# nrf54h20_enga_application register map
Vendor: Nordic Semiconductor; Series: nRF54h; File version: 1
CPU: CM33 r0p4, little endian, MPU, FPU, 3 interrupt priority bits, 480 interrupts, 4 SAU regions
Registers are 32-bit, read-write, reset 0x0 unless marked. A register's access mark holds for its fields unless they carry their own. Offsets are from the block's base; [hi:lo] are bit positions; {n}, {i} and the like mark numbered series; 'fields as' and 'values as' point back to an identical list; <NAME> marks a mode.

## GLOBAL_STM_NS — System Trace Macrocell
Base 0xBF042000
0xC10 DMACTLR — Controls the DMA transfer request mechanism.
  [3:2] SENS — Determines the sensitivity of the DMA request to the current buffer level in the STM
    0=LT25 (Buffer is <25 percent full.); 1=LT50 (Buffer is <50 percent full.); 2=LT75 (Buffer is <75 percent full.); 3=LT100 (Buffer is <100 percent full.)
0xDF4 HEMASTR ro — Indicates the STPv2 master number of hardware event trace. This number is the master number presented in STPv2.
  [16:0] MASTER — The STPv2 master number that hardware event traces should be associated with.
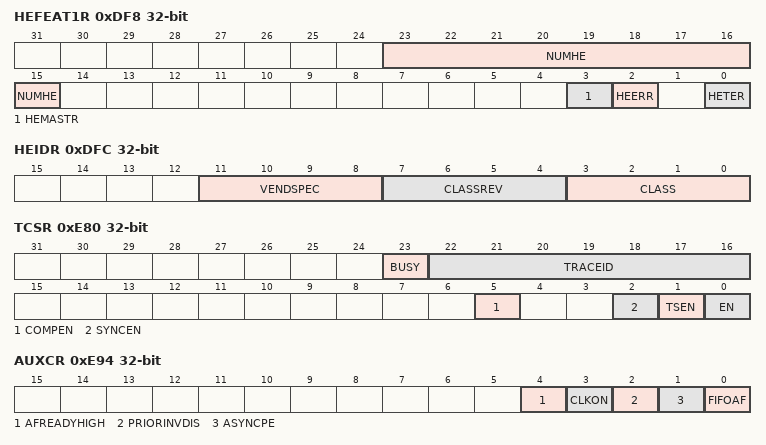
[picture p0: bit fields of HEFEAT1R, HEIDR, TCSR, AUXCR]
0xDF8 HEFEAT1R ro — Indicates the features of the STM.
  [23:15] NUMHE — The number of hardware events supported by the STM
  [3] HEMASTR — STMHEMASTR support
    0=NotImplemented (The feature is not implemented.); 1=Implemented (The feature is implemented.)
  [2] HEERR — Hardware event error detection support
    values as HEMASTR
  [0] HETER — STMHETER support
    values as HEMASTR
0xDFC HEIDR ro — Indicates the features of hardware event tracing in the STM.
  [11:8] VENDSPEC — The VENDSPEC field identifies any vendor specific modifications or mappings
  [7:4] CLASSREV — The CLASSREV field identifies the revision of the programmers model
  [3:0] CLASS — The CLASS field identifies the programmers model
    1=Hardware Event Control programmers model
0xE80 TCSR — Controls the STM settings.
  [23] BUSY — STM is busy, for example the STM trace FIFO is not empty.
    0=Ready (STM is not busy.); 1=Busy (STM is busy.)
  [22:16] TRACEID — ATB Trace ID. Setting this value to all zeroes might result in Unpredictable tracing.
  [5] COMPEN — Compression Enable for Stimulus Ports.
    0=Disabled (Compression disabled, data transfers are transmitted at the size of the transaction.); 1=Enabled (Compression enabled, data transfers are compressed to save bandwidth.)
  [2] SYNCEN — STMSYNCR is implemented so this value is Read As One.
    0=Disabled (The STM Sync feature is disabled.); 1=Enabled (The STM Sync feature is enabled.)
  [1] TSEN — Enable or disable timestamp bundling.
    0=Disabled (Time stamps are disabled. Requests for timestamp generation are ignored, and stimulus port writes selecting timestamping are treated as if it were not selected.); 1=Enabled (Time stamps are enabled. If stimulus writes select timestamping, a timestamp is output according to STPv2.)
  [0] EN — Global STM enable
    0=Disabled (The STM is disabled.); 1=Enabled (The STM is enabled.)
0xE94 AUXCR — Used for implementation defined STM controls.
  [4] AFREADYHIGH — Provides override control for the AFREADY output
    0=Disabled (No override, AFREADY is controlled by the state of STM.); 1=Enabled (Override, AFREADY is driven HIGH.)
  [3] CLKON — Provides override control for architectural clock gate enable.
    0=Disabled (No override, clock gate is controlled by the state of STM.); 1=Enabled (Override, clock is enabled.)
  [2] PRIORINVDIS — Controls arbitration between AXI and HW during flush.
    0=Enabled (Priority inversion, when AXI flush is finished, HW gets priority until HW flush is done.); 1=Disabled (Priority inversion disabled, AXI always has priority over HW.)
  [1] ASYNCPE — Is ASYNC priority higher than trace?
    0=Lower (ASYNC priority is always lower than trace.); 1=Escalate (ASYNC priority escalates on second synchronization request.)
  [0] FIFOAF — FIFO Auto-flush.
    0=Disabled (Auto-flush is disabled.); 1=Enabled (Auto-flush is enabled. The STM automatically drains all data it has even if the ATB interface is not fully utilized.)
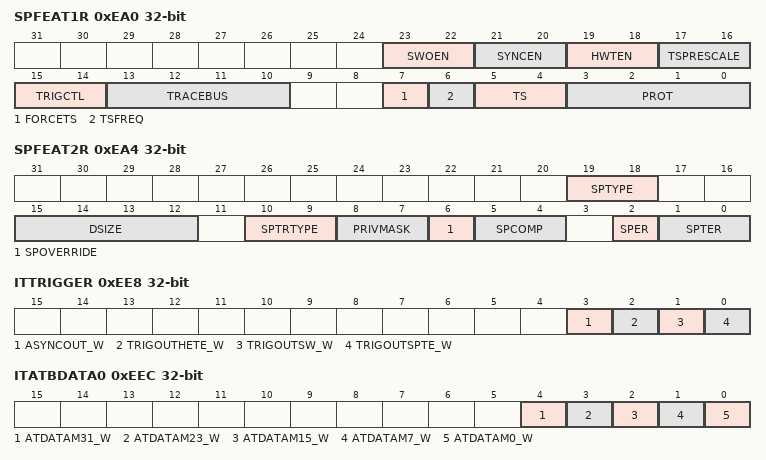
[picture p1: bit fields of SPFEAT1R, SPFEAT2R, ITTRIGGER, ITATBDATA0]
0xEA0 SPFEAT1R — Indicates the features of the STM.
  [23:22] SWOEN — STMTCSR.SWOEN support
    1=NotImplemented (STMTCSR.SWOEN not implemented)
  [21:20] SYNCEN — STMTCSR.SYNCEN support
    2=ReadAsOne (STMTCSR.SYNCEN implemented but always reads as b1)
  [19:18] HWTEN — STMTCSR.HWTEN support
    1=NotImplemented (STMTCSR.HWTEN is not implemented)
  [17:16] TSPRESCALE — Timestamp prescale support
    0=NotImplemented (Timestamp prescale is not implemented.); 1=Implemented (Timestamp prescale is implemented.)
  [15:14] TRIGCTL — Trigger control support.
  [13:10] TRACEBUS — Trace bus support.
  [7] FORCETS — Timestamp force configuration.
    0=NotImplemented (STMTSSTIMR bit 0 is read-only.); 1=Implemented (STMTSSTIMR bit 0 is read-write.)
  [6] TSFREQ — Timestamp frequency indication configuration.
    0=NotImplemented (STMTSFREQR is read-only.); 1=Implemented (STMTSFREQR is read-write.)
  [5:4] TS — Timestamp support.
    1=Absolute timestamps implemented
  [3:0] PROT — Indicates the implemented STM protocol.
    1=STPV2 (STM implements the STPV2 protocol.)
0xEA4 SPFEAT2R — Indicates the features of the STM.
  [19:18] SPTYPE — Stimulus port type support
    1=Only extended stimulus ports are implemented
  [15:12] DSIZE — Fundamental data size.
    0=Bits32 (32-bit data.)
  [10:9] SPTRTYPE — Stimulus port transaction type support.
    2=InvariantAndGuaranteed (Both invariant timing and guaranteed transactions are supported.)
  [8:7] PRIVMASK — STMPRIVMASKR support.
    1=NotImplemented (STMPRIVMASKR is not implemented.)
  [6] SPOVERRIDE — Timestamp force configuration.
    0=NotImplemented (STMSPOVERRIDER and STMSPMOVERRIDER is not implemented.); 1=Implemented (STMSPOVERRIDER and STMSPMOVERRIDER is implemented.)
  [5:4] SPCOMP — Data compression on stimulus ports support.
    3=Programmable (Data compression support is programmable. STMTCSR.COMPEN is implemented.)
  [2] SPER — STMSPER presence.
    0=Implemented (STMSPER is implemented.); 1=NotImplemented (STMSPER is not implemented.)
  [1:0] SPTER — STMSPTER support.
    2=Implemented (STMSPTER is implemented.)
0xEA8 SPFEAT3R — Indicates the features of the STM.
  [6:0] NUMMAST — The number of stimulus ports masters implemented, minus 1.
    63=Masters128 (Example: 128 masters implemented.)
0xEE8 ITTRIGGER wo — Integration Test for Cross-Trigger Outputs Register.
  [all] fields
    0=Low (Drive logic 0 on output.); 1=High (Drive logic 1 on output.)
  [3] ASYNCOUT_W — Sets the value of the ASYNCOUT output in integration mode.
  [2] TRIGOUTHETE_W — Sets the value of the TRIGOUTHETE output in integration mode.
  [1] TRIGOUTSW_W — Sets the value of the TRIGOUTSW output in integration mode.
  [0] TRIGOUTSPTE_W — Sets the value of the TRIGOUTSPTE output in integration mode.
0xEEC ITATBDATA0 wo — Controls the value of the ATDATAM output in integration mode.
  [all] fields
    values as the fields of ITTRIGGER
  [4] ATDATAM31_W — Sets the value of the ATDATAM[31].
  [3] ATDATAM23_W — Sets the value of the ATDATAM[23].
  [2] ATDATAM15_W — Sets the value of the ATDATAM[15].
  [1] ATDATAM7_W — Sets the value of the ATDATAM[7] output.
  [0] ATDATAM0_W — Sets the value of the ATDATAM[0].
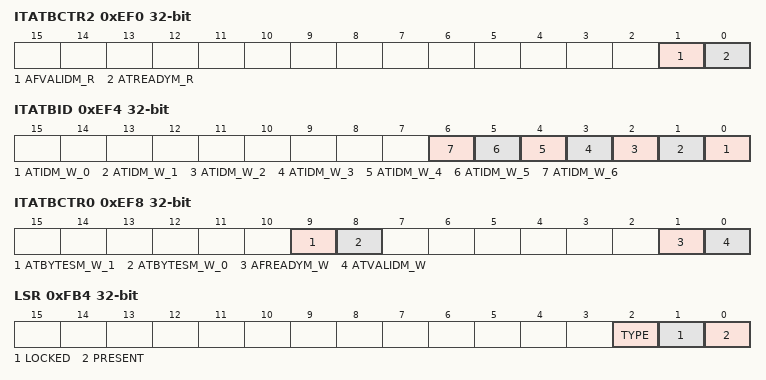
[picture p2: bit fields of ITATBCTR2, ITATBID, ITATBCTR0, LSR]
0xEF0 ITATBCTR2 wo — Controls the value of the ATDATAM output in integration mode.
  [1] AFVALIDM_R — Reads the value of the AFVALIDM input.
    0=Low (Pin is at logic 0.); 1=High (Pin is at logic 1.)
  [0] ATREADYM_R — Reads the value of the ATREADYM input.
    0=Low (Pin is at logic 0.); 1=High (Pin is at logic 1.)
0xEF4 ITATBID wo — Controls the value of the ATIDM output in integration mode.
  [all] fields
    0=Low (Pin is at logic 0.); 1=High (Pin is at logic 1.)
  [n] ATIDM_W_{n} (n=0..6) — Sets the value of pin {n} of the ATIDM output.
0xEF8 ITATBCTR0 wo — Controls the value of the ATVALIDM, AFREADYM, and ATBYTESM outputs in integration mode.
  [all] fields
    0=Low (Pin is at logic 0.); 1=High (Pin is at logic 1.)
  [9] ATBYTESM_W_1 — Sets the value of pin 1 of the ATBYTESM output.
  [8] ATBYTESM_W_0 — Sets the value of pin 0 of the ATBYTESM output.
  [1] AFREADYM_W — Sets the value of the AFREADYM_W output.
  [0] ATVALIDM_W — Sets the value of the ATVALIDM output.
0xF00 ITCTRL — Used to enable topology detection. This register enables the component to switch from a functional mode, the default behavior, to integration mode where the inputs and outputs of the component can be directly controlled for integration testing and topology solving.
  [0] INTEGRATIONMODE — Enables the component to switch from functional mode to integration mode and back. If no integration functionality is implemented, this register must read as zero.
    0=Disabled (Integration mode is disabled.); 1=Enabled (Integration mode is Enabled.)
0xFB0 LAR — This is used to enable write access to device registers.
  [31:0] ACCESS — A write of 0xC5ACCE55 enables further write access to this device. Any other write removes write access.
    0xC5ACCE55=Unlock register interface
0xFB4 LSR — This indicates the status of the lock control mechanism. This lock prevents accidental writes by code under debug. Accesses to the extended stimulus port registers are not affected by the lock mechanism. This register must always be present although there might not be any lock access control mechanism. The lock mechanism, where present and locked, must block write accesses to any control register, except the Lock Access Register. For most components this covers all registers except for the Lock Access Register.
  [2] TYPE — Indicates if the Lock Access Register is implemented as 8-bit or 32-bit.
    0=Bits32 (This component implements a 32-bit Lock Access Register.); 1=Bits8 (This component implements an 8-bit Lock Access Register.)
  [1] LOCKED — Returns the current status of the Lock.
    0=UnLocked (Write access is allowed to this device.); 1=Locked (Write access to the component is blocked. All writes to control registers are ignored. Reads are permitted.)
  [0] PRESENT — Indicates that a lock control mechanism exists for this device.
    0=NotImplemented (No lock control mechanism exists, writes to the Lock Access Register are ignored.); 1=Implemented (Lock control mechanism is present.)
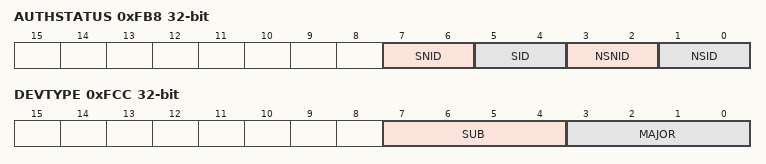
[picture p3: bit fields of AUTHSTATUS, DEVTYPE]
0xFB8 AUTHSTATUS — Indicates the current level of tracing permitted by the system
  [all] fields
    values as HEFEAT1R.HEMASTR
  [7:6] SNID — Secure Non-Invasive Debug
  [5:4] SID — Secure Invasive Debug
  [3:2] NSNID — Non-secure Non-Invasive Debug
  [1:0] NSID — Non-secure Invasive Debug
0xFC8 DEVID ro — Indicates the capabilities of the STM.
  [16:0] NUMSP — This value indicates the number of stimulus ports implemented.
    0x10000=Max (Maximum 65,536 stimulus ports can be implemented.)
0xFCC DEVTYPE ro — Controls the single-shot comparator.
  [7:4] SUB — The sub-type of the component
    6=StimulusTrace (Peripheral is a stimulus trace source.)
  [3:0] MAJOR — The main type of the component
    3=TraceSource (Peripheral is a trace source.)
0xFD0 PIDR4 — Coresight peripheral identification registers.
{0xFE0+4i} PIDR_{i} (i=0..3) — Coresight peripheral identification registers.
{0xFF0+4i} CIDR_{i} (i=0..3) — Coresight component identification registers.
